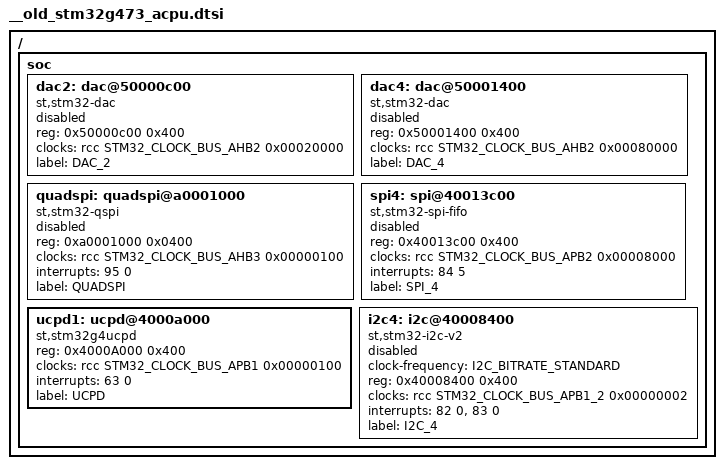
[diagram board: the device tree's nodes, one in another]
/*
 * Copyright (c) 2021 Acme CPU
 *
 */

#include <st/g4/stm32g4.dtsi>

/ {
	soc {

		dac2: dac@50000c00 {
			compatible = "st,stm32-dac";
			reg = <0x50000c00 0x400>;
			clocks = <&rcc STM32_CLOCK_BUS_AHB2 0x00020000>;
			status = "disabled";
			label = "DAC_2";
			#io-channel-cells = <1>;
		};

		dac4: dac@50001400 {
			compatible = "st,stm32-dac";
			reg = <0x50001400 0x400>;
			clocks = <&rcc STM32_CLOCK_BUS_AHB2 0x00080000>;
			status = "disabled";
			label = "DAC_4";
			#io-channel-cells = <1>;
		};
		
		quadspi: quadspi@a0001000 {
			compatible = "st,stm32-qspi";
			#address-cells = <1>;
			#size-cells = <0>;
			reg = <0xa0001000 0x0400>;							/* RM0440 ref manual: Pg. 82, table 3 */
			clocks = <&rcc STM32_CLOCK_BUS_AHB3 0x00000100>;	
			interrupts = <95 0>;								/* RM0440 ref manual: Pg. 445, table 97 */
			status = "disabled";
			label = "QUADSPI";
		};
		
		spi4: spi@40013c00 {
			compatible = "st,stm32-spi-fifo", "st,stm32-spi";
			#address-cells = <1>;
			#size-cells = <0>;
			reg = <0x40013c00 0x400>;
			clocks = <&rcc STM32_CLOCK_BUS_APB2 0x00008000>;
			interrupts = <84 5>;
			status = "disabled";
			label = "SPI_4";
		};
		
		/* TODO: remove the ucpd node as it has been added in stm32g4.dtsi file inside zephyr repo */
		ucpd1: ucpd@4000a000 {
			compatible = "st,stm32g4ucpd";
			#address-cells = <1>;
			#size-cells = <0>;
			reg = <0x4000A000 0x400>;							/* RM0440 ref manual: Pg. 84, table 3 */
			clocks = <&rcc STM32_CLOCK_BUS_APB1 0x00000100>;	/* RM0440 ref manual: Pg. 314, sec. 7.4.18 */
			interrupts = <63 0>;								/* RM0440 ref manual: Pg. 444, table 97 */
			interrupt-names = "global";
			status = "okay";
			label = "UCPD";
		};
		
		i2c4: i2c@40008400 {
			compatible = "st,stm32-i2c-v2";
			clock-frequency = <I2C_BITRATE_STANDARD>;
			#address-cells = <1>;
			#size-cells = <0>;
			reg = <0x40008400 0x400>;
			clocks = <&rcc STM32_CLOCK_BUS_APB1_2 0x00000002>;
			interrupts = <82 0>, <83 0>;
			interrupt-names = "event", "error";
			status = "disabled";
			label= "I2C_4";
		};
		
	};
};
